# AT32F413 register map
Vendor: Keil; Series: AT32F413; File version: 1.0
CPU: CM4 r0p1, little endian, no MPU, FPU, 4 interrupt priority bits
Registers are 32-bit, read-write, reset 0x0 unless marked. A register's access mark holds for its fields unless they carry their own. Offsets are from the block's base; [hi:lo] are bit positions; {n}, {i} and the like mark numbered series; 'fields as' and 'values as' point back to an identical list.

## WWDT — Window watchdog
Base 0x40002C00
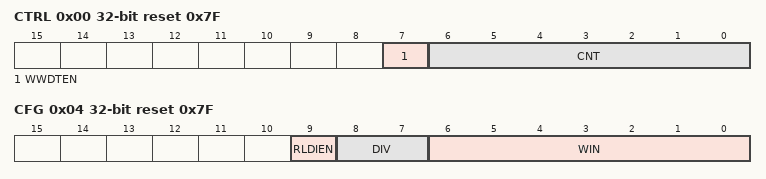
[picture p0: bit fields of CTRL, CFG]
0x00 CTRL reset 0x7F — Control register
  [7] WWDTEN write-1-sets — Window watchdog enable
    on read: 0=Disabled; 1=Enabled | on write: 1=Enable
  [6:0] CNT — Decrement counter
0x04 CFG reset 0x7F — Configuration register
  [9] RLDIEN — Reload counter interrupt
    on read: 0=Disabled; 1=Enabled | on write: 0=Disable; 1=Enable
  [8:7] DIV — Clock division value
    0=PCLK1 divided by 4096; 1=PCLK1 divided by 8192; 2=PCLK1 divided by 16384; 3=PCLK1 divided by 32768
  [6:0] WIN — Window value
0x08 STS — Status register
  [0] RLDF write-0-clears — Reload counter interrupt flag
    on read: 0=NotReached (Downcounter doesn't reached 0x40); 1=Reached (Downcounter reached 0x40) | on write: 0=Clear flag

## ACC — HICK Auto Clock Calibration
Base 0x40015800
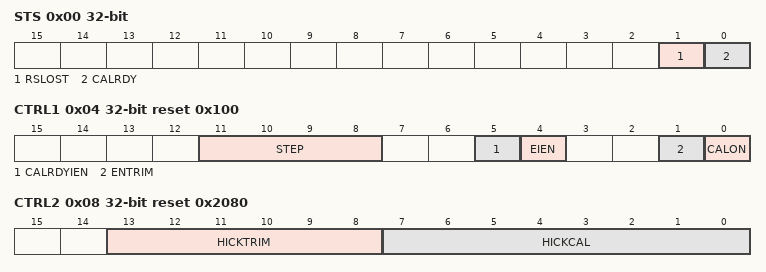
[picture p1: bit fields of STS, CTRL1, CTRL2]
0x00 STS ro — status register
  [1] RSLOST rw — Reference Signal Lost
    0=NotLost (Reference Signal is not lost); 1=Lost (Reference Signal is lost)
  [0] CALRDY rw — Internal high-speed clock calibration ready
    0=NotReady (Interal 8MHz oscillator calibration is not ready); 1=Ready (Interal 8MHz oscillator calibration is ready)
0x04 CTRL1 reset 0x100 — control register 1
  [11:8] STEP — Calibrated step
  [5] CALRDYIEN — CALRDY interrupt enable
    on read: 0=Disabled (Interrupt generation disabled); 1=Enabled (ACC interrupt is generated when CALRDY=1 in the ACC_STS register) | on write: 0=Disable (Interrupt generation disabled); 1=Enable (ACC interrupt is generated when CALRDY=1 in the ACC_STS register)
  [4] EIEN — RSLOST error interrupt enable
    on read: 0=Disabled (Interrupt generation disabled); 1=Enabled (ACC interrupt is generated when RSLOST=1 in the ACC_STS register) | on write: 0=Disable (Interrupt generation disabled); 1=Enable (ACC interrupt is generated when RSLOST=1 in the ACC_STS register)
  [1] ENTRIM — Enable trim
    0=HICKCAL (HICKCAL is calibrated); 1=HICKTRIM (HICKTRIM is calibrated)
  [0] CALON — Calibration on
    on read: 0=Disabled (Calibration disabled); 1=Enabled (Calibration enabled, and starts searching for a pulse on the USB_SOF) | on write: 0=Disable (Calibration disabled); 1=Enable (Calibration enabled, and starts searching for a pulse on the USB_SOF)
0x08 CTRL2 reset 0x2080 — control register 2
  [13:8] HICKTRIM ro — Internal high-speed auto clock trimming
  [7:0] HICKCAL ro — Internal high-speed auto clock calibration
0x0C C1 reset 0x1F2C — compare value 1
  [15:0] C1 — Compare 1
0x10 C2 reset 0x1F40 — compare value 2
  [15:0] C2 — Compare 2
0x14 C3 reset 0x1F54 — compare value 3
  [15:0] C3 — Compare 3

## DEBUG — Debug support
Base 0xE0042000
0x00 IDCODE ro — DEBUG_IDCODE
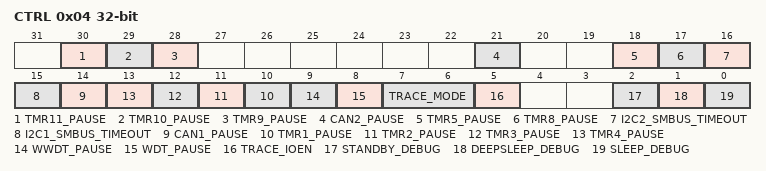
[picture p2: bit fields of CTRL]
0x04 CTRL — DEBUG_CTRL
  [30] TMR11_PAUSE — Timer pause control bit
    0=Continue (The counter clock of TMRx is fed even if the core is halted); 1=Pause (The counter clock of TMRx is stopped when the core is halted)
  [29] TMR10_PAUSE — Timer pause control bit
    values as TMR11_PAUSE
  [28] TMR9_PAUSE — Timer pause control bit
    values as TMR11_PAUSE
  [21] CAN2_PAUSE
  [18] TMR5_PAUSE — Timer pause control bit
    values as TMR11_PAUSE
  [17] TMR8_PAUSE — Timer pause control bit
    values as TMR11_PAUSE
  [16] I2C2_SMBUS_TIMEOUT
  [15] I2C1_SMBUS_TIMEOUT
  [14] CAN1_PAUSE
  [n+9] TMR{n}_PAUSE (n=1..4) — Timer pause control bit
    values as TMR11_PAUSE
  [9] WWDT_PAUSE
    values as TMR11_PAUSE
  [8] WDT_PAUSE
    values as TMR11_PAUSE
  [7:6] TRACE_MODE
  [5] TRACE_IOEN
  [2] STANDBY_DEBUG — Debug Standby mode control bit
    on read: 0=Disabled (The whole 1.2V digital circuit is unpowered in Standby mode); 1=Enabled (The whole 1.2V digital circuit is not unpowered in Standby mode, and the system clock is provided by the internal RC oscillator (HICK)) | on write: 0=Disable (The whole 1.2V digital circuit is unpowered in Standby mode); 1=Enable (The whole 1.2V digital circuit is not unpowered in Standby mode, and the system clock is provided by the internal RC oscillator (HICK))
  [1] DEEPSLEEP_DEBUG — Debug Deepsleep mode control bit
    on read: 0=Disabled (In Deepsleep mode, all clocks in the 1.2V domain are disabled); 1=Enabled (In Deepsleep mode, system clock is provided by the internal RC oscillator (HICK)) | on write: 0=Disable (In Deepsleep mode, all clocks in the 1.2V domain are disabled); 1=Enable (In Deepsleep mode, system clock is provided by the internal RC oscillator (HICK))
  [0] SLEEP_DEBUG — Debug Sleep mode control bit
    on read: 0=Disabled (When entering Sleep mode, CPU HCLK clock is disabled, but other clocks remain active); 1=Enabled (When entering Sleep mode, all clocks keep running) | on write: 0=Disable (When entering Sleep mode, CPU HCLK clock is disabled, but other clocks remain active); 1=Enable (When entering Sleep mode, all clocks keep running)

## CRC — CRC calculation unit
Base 0x40023000
0x00 DT reset 0xFFFFFFFF — Data register
0x04 CDT — Common data register
  [7:0] CDT — Common Data
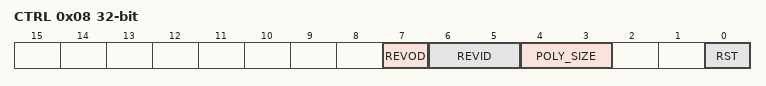
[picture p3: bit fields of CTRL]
0x08 CTRL — Control register
  [7] REVOD — Reverse output data
    0=NoEffect; 1=WordReverse
  [6:5] REVID — Reverse input data
    0=NoEffect; 1=ByteReverse; 2=HalfWordReverse; 3=WordReverse
  [4:3] POLY_SIZE — Polynomial size
    0=bits32 (32 bits); 1=bits16 (16 bits); 2=bits8 (8 bits); 3=bits7 (7 bits)
  [0] RST write-1-sets — Reset bit
    on write: 1=Reset CRC calculation unit, the data register is set as 0xFFFF FFFF
0x10 IDT reset 0xFFFFFFFF — Initial data register
0x14 POLY reset 0x4C11DB7 — Polynomial coefficient register

## NVIC — Nested Vectored Interrupt Controller
Base 0xE000E000
0x04 ICTR ro — Interrupt Controller Type Register
  [3:0] INTLINESNUM — Total number of interrupt lines in groups
0x100 ISER0 — Interrupt Set-Enable Register
  [31:0] SETENA
0x104 ISER1 — Interrupt Set-Enable Register
  [31:0] SETENA
0x180 ICER0 — Interrupt Clear-Enable Register
  [31:0] CLRENA
0x184 ICER1 — Interrupt Clear-Enable Register
  [31:0] CLRENA
0x200 ISPR0 — Interrupt Set-Pending Register
  [31:0] SETPEND
0x204 ISPR1 — Interrupt Set-Pending Register
  [31:0] SETPEND
0x280 ICPR0 — Interrupt Clear-Pending Register
  [31:0] CLRPEND
0x284 ICPR1 — Interrupt Clear-Pending Register
  [31:0] CLRPEND
0x300 IABR0 ro — Interrupt Active Bit Register
  [31:0] ACTIVE
0x304 IABR1 ro — Interrupt Active Bit Register
  [31:0] ACTIVE
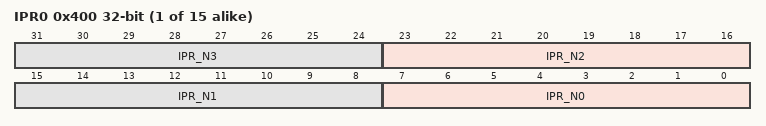
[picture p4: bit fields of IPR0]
{0x400+4i} IPR{i} (i=0..14) — Interrupt Priority Register
  [8n+7:8n] IPR_N{n} (n=0..3)
0xF00 STIR wo — Software Triggered Interrupt Register
  [8:0] INTID — interrupt to be triggered

## USBFS — Universal serial bus full-speed device interface
Base 0x40005C00
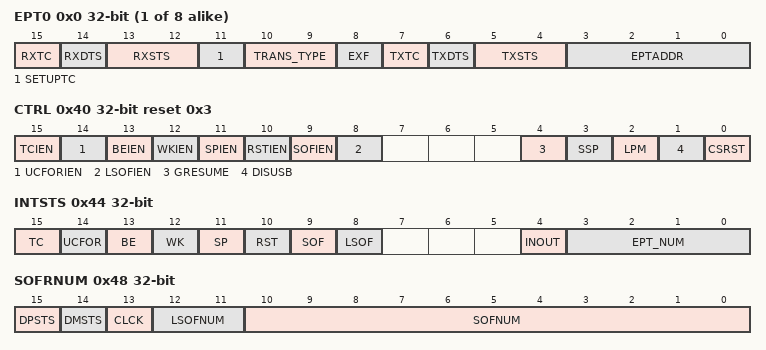
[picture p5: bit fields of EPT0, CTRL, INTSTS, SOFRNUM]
{0x0+4i} EPT{i} (i=0..7) — endpoint {i} register
  [15] RXTC — Rx transaction completed
  [14] RXDTS — Rx data toggle synchronization
  [13:12] RXSTS — Rx Status
  [11] SETUPTC — Setup transaction completed
  [10:9] TRANS_TYPE — Transfer type
  [8] EXF — Endpoint extend function
  [7] TXTC — Tx transaction completed
  [6] TXDTS — Tx data toggle synchronization
  [5:4] TXSTS — Tx status
  [3:0] EPTADDR — Endpoint address
0x40 CTRL reset 0x3 — control register
  [15] TCIEN — transmission completed interrupt enable
  [14] UCFORIEN — USB Core fifo overrun interrupt enable
  [13] BEIEN — Bus error interrupt enable
  [12] WKIEN — Wakeup/Remote wakeup interrupt enable
  [11] SPIEN — Bus suspend mode interrupt enable
  [10] RSTIEN — Bus reset interrupt enable
  [9] SOFIEN — Start of frame interrupt enable
  [8] LSOFIEN — Lost start of frame interrupt enable
  [4] GRESUME — Generate resume request
  [3] SSP — Soft suspend config
  [2] LPM — Low power mode
  [1] DISUSB — Disable usb phy
  [0] CSRST — Core soft reset
0x44 INTSTS — interrupt status register
  [15] TC — transaction completed
  [14] UCFOR — USB core fifo overrun memory
  [13] BE — Bus error
  [12] WK — Wakeup
  [11] SP — Bus suspend
  [10] RST — Bus reset
  [9] SOF — start of frame
  [8] LSOF — Lost start of frame
  [4] INOUT — In/Out transaction
  [3:0] EPT_NUM — Endpoint number
0x48 SOFRNUM — frame number register
  [15] DPSTS — DP status
  [14] DMSTS — DM status
  [13] CLCK — Connect locked
  [12:11] LSOFNUM — Lost start of frame number
  [10:0] SOFNUM — Start of frame number
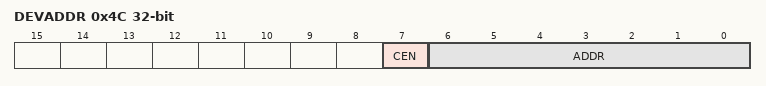
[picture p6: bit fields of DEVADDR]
0x4C DEVADDR — device address
  [7] CEN — USB core enable
  [6:0] ADDR — Host assign device address
0x50 BUFTBL — Buffer table address
  [15:3] BTADDR — Endpoint buffer table start address
0x60 CFG — CFG control register
  [0] SOFOUTEN — SOF output enable
